# PIC32MX695F512L register map
Registers are 32-bit, access not given, reset 0x0 unless marked. A register's access mark holds for its fields unless they carry their own. Offsets are from the block's base; [hi:lo] are bit positions; 'fields as' and 'values as' point back to an identical list.

## ICAP1 — ICAP1 peripheral
Base 0xBF802000
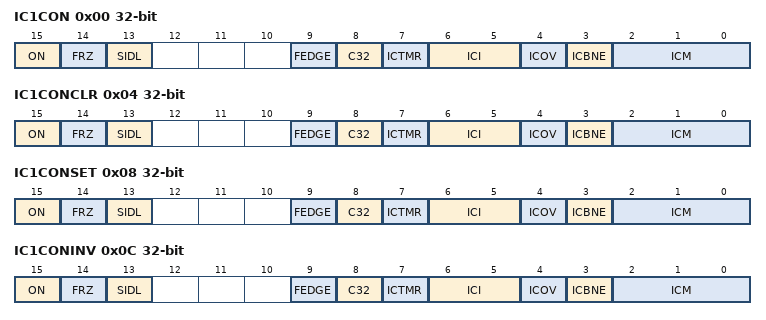
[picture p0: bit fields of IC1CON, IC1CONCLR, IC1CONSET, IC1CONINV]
0x00 IC1CON
  [15] ON, [14] FRZ, [13] SIDL, [9] FEDGE, [8] C32, [7] ICTMR, [6:5] ICI, [4] ICOV, [3] ICBNE, [2:0] ICM
0x04 IC1CONCLR
  fields as IC1CON
0x08 IC1CONSET
  fields as IC1CON
0x0C IC1CONINV
  fields as IC1CON
0x10 IC1BUF

## ICAP2 — ICAP2 peripheral
Base 0xBF802200
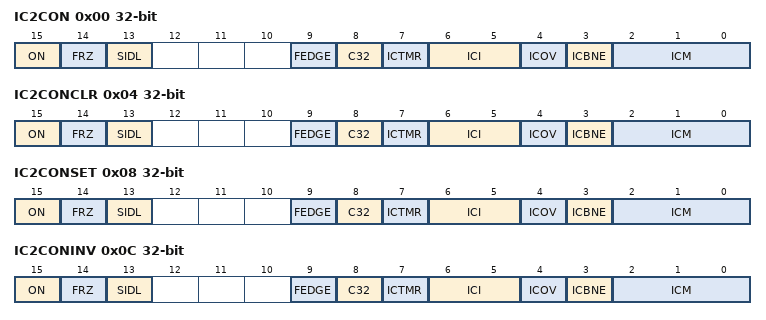
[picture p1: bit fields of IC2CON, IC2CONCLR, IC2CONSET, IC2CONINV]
0x00 IC2CON
  [15] ON, [14] FRZ, [13] SIDL, [9] FEDGE, [8] C32, [7] ICTMR, [6:5] ICI, [4] ICOV, [3] ICBNE, [2:0] ICM
0x04 IC2CONCLR
  fields as IC2CON
0x08 IC2CONSET
  fields as IC2CON
0x0C IC2CONINV
  fields as IC2CON
0x10 IC2BUF

## ICAP3 — ICAP3 peripheral
Base 0xBF802400
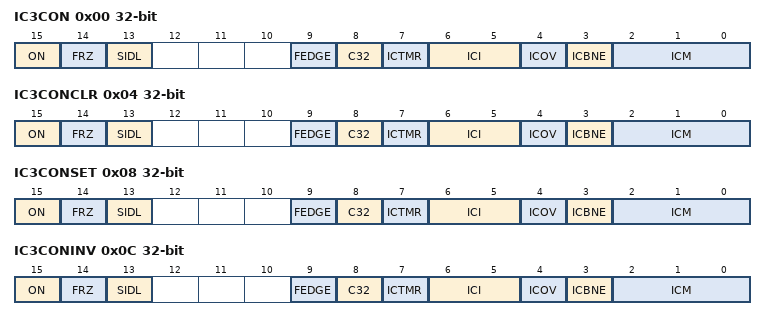
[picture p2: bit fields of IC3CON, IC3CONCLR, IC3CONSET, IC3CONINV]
0x00 IC3CON
  [15] ON, [14] FRZ, [13] SIDL, [9] FEDGE, [8] C32, [7] ICTMR, [6:5] ICI, [4] ICOV, [3] ICBNE, [2:0] ICM
0x04 IC3CONCLR
  fields as IC3CON
0x08 IC3CONSET
  fields as IC3CON
0x0C IC3CONINV
  fields as IC3CON
0x10 IC3BUF

## ICAP4 — ICAP4 peripheral
Base 0xBF802600
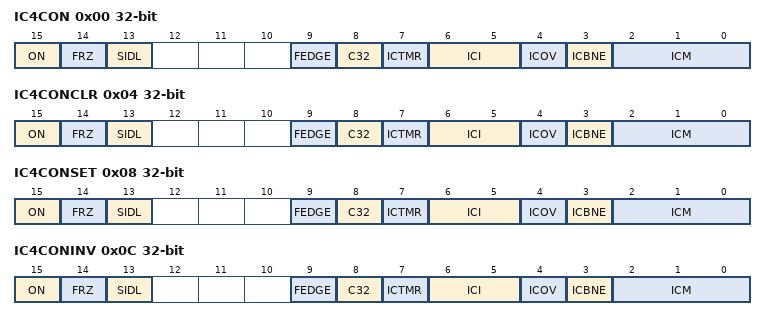
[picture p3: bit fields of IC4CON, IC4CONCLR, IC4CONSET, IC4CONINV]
0x00 IC4CON
  [15] ON, [14] FRZ, [13] SIDL, [9] FEDGE, [8] C32, [7] ICTMR, [6:5] ICI, [4] ICOV, [3] ICBNE, [2:0] ICM
0x04 IC4CONCLR
  fields as IC4CON
0x08 IC4CONSET
  fields as IC4CON
0x0C IC4CONINV
  fields as IC4CON
0x10 IC4BUF

## ICAP5 — ICAP5 peripheral
Base 0xBF802800
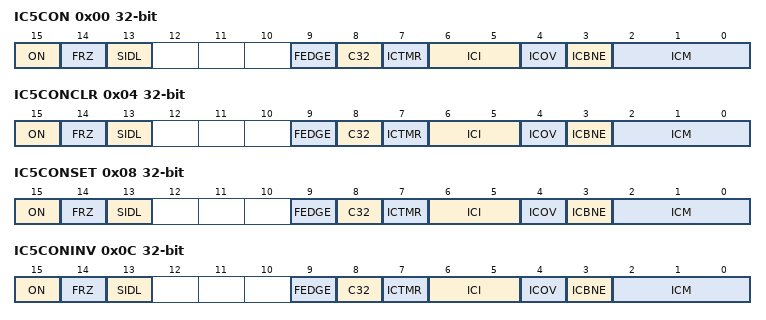
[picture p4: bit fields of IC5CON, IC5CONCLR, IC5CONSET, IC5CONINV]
0x00 IC5CON
  [15] ON, [14] FRZ, [13] SIDL, [9] FEDGE, [8] C32, [7] ICTMR, [6:5] ICI, [4] ICOV, [3] ICBNE, [2:0] ICM
0x04 IC5CONCLR
  fields as IC5CON
0x08 IC5CONSET
  fields as IC5CON
0x0C IC5CONINV
  fields as IC5CON
0x10 IC5BUF

## OCMP1 — OCMP1 peripheral
Base 0xBF803000
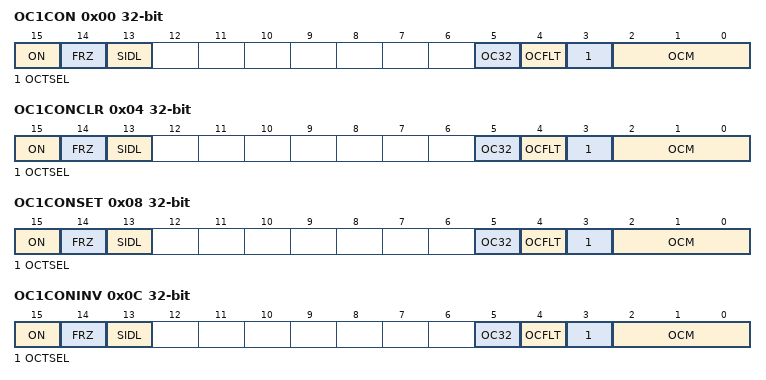
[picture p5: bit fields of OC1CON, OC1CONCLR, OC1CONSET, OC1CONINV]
0x00 OC1CON
  [15] ON, [14] FRZ, [13] SIDL, [5] OC32, [4] OCFLT, [3] OCTSEL, [2:0] OCM
0x04 OC1CONCLR
  fields as OC1CON
0x08 OC1CONSET
  fields as OC1CON
0x0C OC1CONINV
  fields as OC1CON
0x10 OC1R
0x14 OC1RCLR
  [31:0] OC1R
0x18 OC1RSET
  [31:0] OC1R
0x1C OC1RINV
  [31:0] OC1R
0x20 OC1RS
0x24 OC1RSCLR
  [31:0] OC1RS
0x28 OC1RSSET
  [31:0] OC1RS
0x2C OC1RSINV
  [31:0] OC1RS

## OCMP2 — OCMP2 peripheral
Base 0xBF803200
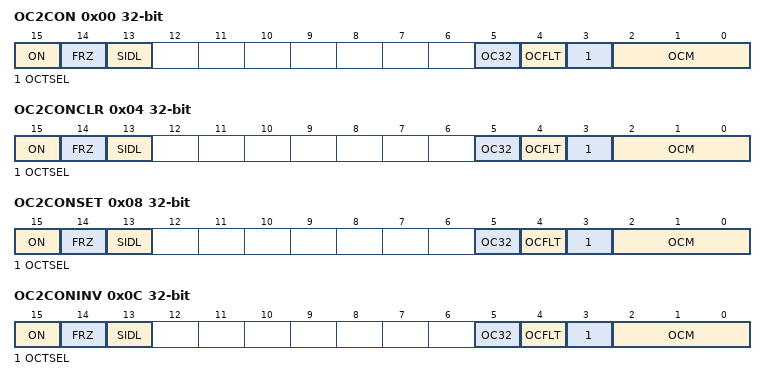
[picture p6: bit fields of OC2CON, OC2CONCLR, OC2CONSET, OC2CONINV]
0x00 OC2CON
  [15] ON, [14] FRZ, [13] SIDL, [5] OC32, [4] OCFLT, [3] OCTSEL, [2:0] OCM
0x04 OC2CONCLR
  fields as OC2CON
0x08 OC2CONSET
  fields as OC2CON
0x0C OC2CONINV
  fields as OC2CON
0x10 OC2R
0x14 OC2RCLR
  [31:0] OC2R
0x18 OC2RSET
  [31:0] OC2R
0x1C OC2RINV
  [31:0] OC2R
0x20 OC2RS
0x24 OC2RSCLR
  [31:0] OC2RS
0x28 OC2RSSET
  [31:0] OC2RS
0x2C OC2RSINV
  [31:0] OC2RS

## OCMP3 — OCMP3 peripheral
Base 0xBF803400
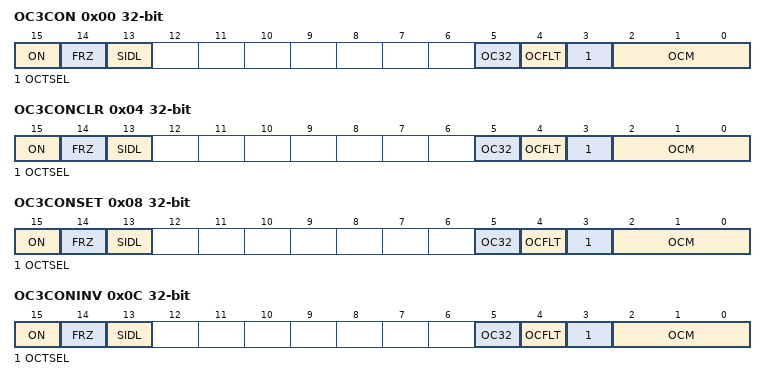
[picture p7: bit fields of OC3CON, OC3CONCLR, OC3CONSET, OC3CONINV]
0x00 OC3CON
  [15] ON, [14] FRZ, [13] SIDL, [5] OC32, [4] OCFLT, [3] OCTSEL, [2:0] OCM
0x04 OC3CONCLR
  fields as OC3CON
0x08 OC3CONSET
  fields as OC3CON
0x0C OC3CONINV
  fields as OC3CON
0x10 OC3R
0x14 OC3RCLR
  [31:0] OC3R
0x18 OC3RSET
  [31:0] OC3R
0x1C OC3RINV
  [31:0] OC3R
0x20 OC3RS
0x24 OC3RSCLR
  [31:0] OC3RS
0x28 OC3RSSET
  [31:0] OC3RS
0x2C OC3RSINV
  [31:0] OC3RS

## OCMP4 — OCMP4 peripheral
Base 0xBF803600
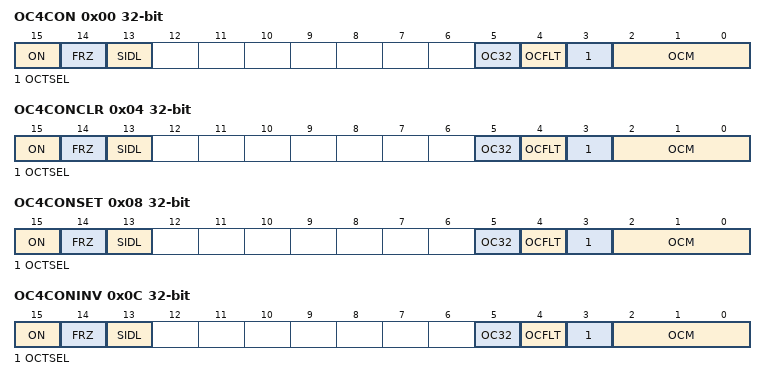
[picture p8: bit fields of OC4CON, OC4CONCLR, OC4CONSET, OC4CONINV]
0x00 OC4CON
  [15] ON, [14] FRZ, [13] SIDL, [5] OC32, [4] OCFLT, [3] OCTSEL, [2:0] OCM
0x04 OC4CONCLR
  fields as OC4CON
0x08 OC4CONSET
  fields as OC4CON
0x0C OC4CONINV
  fields as OC4CON
0x10 OC4R
0x14 OC4RCLR
  [31:0] OC4R
0x18 OC4RSET
  [31:0] OC4R
0x1C OC4RINV
  [31:0] OC4R
0x20 OC4RS
0x24 OC4RSCLR
  [31:0] OC4RS
0x28 OC4RSSET
  [31:0] OC4RS
0x2C OC4RSINV
  [31:0] OC4RS

## OCMP5 — OCMP5 peripheral
Base 0xBF803800
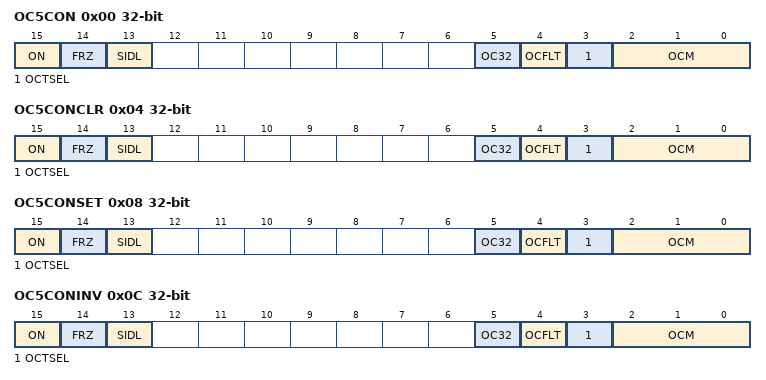
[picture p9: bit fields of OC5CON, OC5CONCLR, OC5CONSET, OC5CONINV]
0x00 OC5CON
  [15] ON, [14] FRZ, [13] SIDL, [5] OC32, [4] OCFLT, [3] OCTSEL, [2:0] OCM
0x04 OC5CONCLR
  fields as OC5CON
0x08 OC5CONSET
  fields as OC5CON
0x0C OC5CONINV
  fields as OC5CON
0x10 OC5R
0x14 OC5RCLR
  [31:0] OC5R
0x18 OC5RSET
  [31:0] OC5R
0x1C OC5RINV
  [31:0] OC5R
0x20 OC5RS
0x24 OC5RSCLR
  [31:0] OC5RS
0x28 OC5RSSET
  [31:0] OC5RS
0x2C OC5RSINV
  [31:0] OC5RS

## I2C3 — I2C3 peripheral
Base 0xBF805000
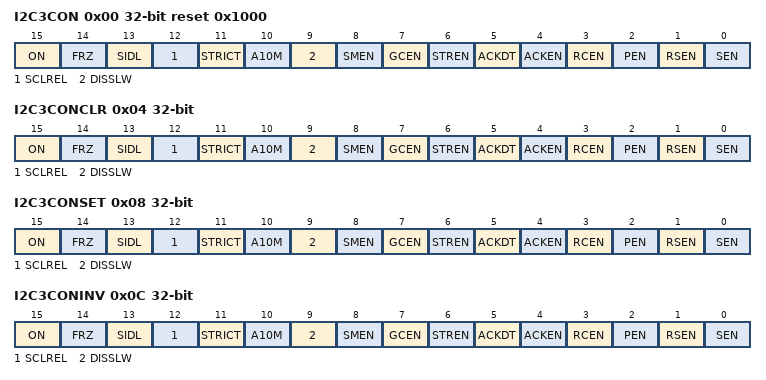
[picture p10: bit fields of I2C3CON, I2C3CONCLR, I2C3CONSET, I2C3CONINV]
0x00 I2C3CON reset 0x1000
  [15] ON, [14] FRZ, [13] SIDL, [12] SCLREL, [11] STRICT, [10] A10M, [9] DISSLW, [8] SMEN, [7] GCEN, [6] STREN, [5] ACKDT, [4] ACKEN, [3] RCEN, [2] PEN, [1] RSEN, [0] SEN
0x04 I2C3CONCLR
  fields as I2C3CON
0x08 I2C3CONSET
  fields as I2C3CON
0x0C I2C3CONINV
  fields as I2C3CON
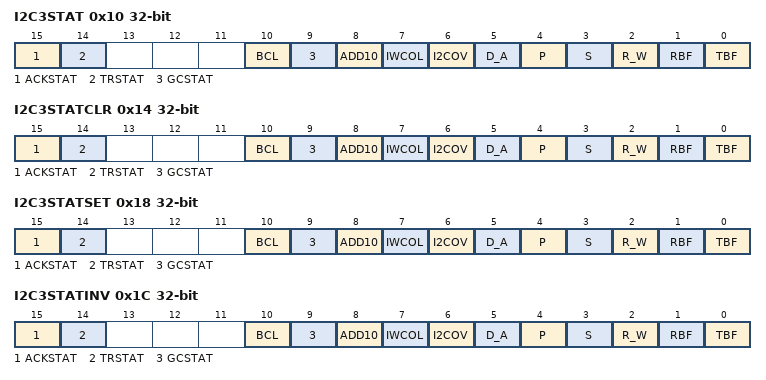
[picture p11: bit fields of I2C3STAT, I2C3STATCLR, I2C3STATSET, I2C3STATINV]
0x10 I2C3STAT
  [15] ACKSTAT, [14] TRSTAT, [10] BCL, [9] GCSTAT, [8] ADD10, [7] IWCOL, [6] I2COV, [5] D_A, [4] P, [3] S, [2] R_W, [1] RBF, [0] TBF
0x14 I2C3STATCLR
  fields as I2C3STAT
0x18 I2C3STATSET
  fields as I2C3STAT
0x1C I2C3STATINV
  fields as I2C3STAT
0x20 I2C3ADD
  [9:0] I2CADD
0x24 I2C3ADDCLR
  [9:0] I2CADD
0x28 I2C3ADDSET
  [9:0] I2CADD
0x2C I2C3ADDINV
  [9:0] I2CADD
0x30 I2C3MSK
  [9:0] I2CMSK
0x34 I2C3MSKCLR
  [9:0] I2CMSK
0x38 I2C3MSKSET
  [9:0] I2CMSK
0x3C I2C3MSKINV
  [9:0] I2CMSK
0x40 I2C3BRG
  [11:0] I2CBRG
0x44 I2C3BRGCLR
  [11:0] I2CBRG
0x48 I2C3BRGSET
  [11:0] I2CBRG
0x4C I2C3BRGINV
  [11:0] I2CBRG
0x50 I2C3TRN
  [7:0] I2CTRN
0x54 I2C3TRNCLR
  [7:0] I2CTRN
0x58 I2C3TRNSET
  [7:0] I2CTRN
0x5C I2C3TRNINV
  [7:0] I2CTRN
0x60 I2C3RCV
  [7:0] I2CRCV

## I2C4 — I2C4 peripheral
Base 0xBF805100
Registers as I2C3 (with I2C3 read as I2C4).

## I2C5 — I2C5 peripheral
Base 0xBF805200
Registers as I2C3 (with I2C3 read as I2C5).

## I2C1 — I2C1 peripheral
Base 0xBF805300
Registers as I2C3 (with I2C3 read as I2C1).

## I2C2 — I2C2 peripheral
Base 0xBF805400
Registers as I2C3 (with I2C3 read as I2C2).
